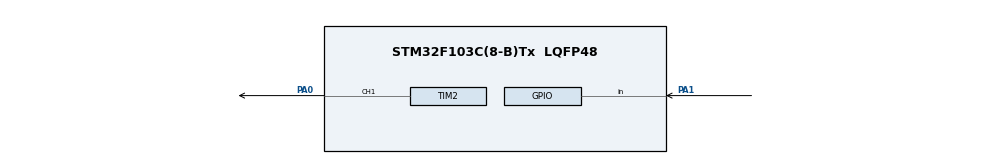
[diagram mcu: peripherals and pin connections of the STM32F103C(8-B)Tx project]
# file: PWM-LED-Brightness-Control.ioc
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Mcu.Family=STM32F1
Mcu.Name=STM32F103C(8-B)Tx
Mcu.Package=LQFP48
NVIC.PriorityGroup=NVIC_PRIORITYGROUP_4
PA0-WKUP.Signal=S_TIM2_CH1_ETR
PA1.GPIO_PuPd=GPIO_PULLUP
PA1.Signal=GPIO_Input
ProjectManager.HeapSize=0x200
ProjectManager.StackSize=0x400
ProjectManager.TargetToolchain=STM32CubeIDE
RCC.APB1Freq_Value=8000000
RCC.APB2Freq_Value=8000000
SH.S_TIM2_CH1_ETR.0=TIM2_CH1,PWM Generation1 CH1
TIM2.Channel-PWM\ Generation1\ CH1=TIM_CHANNEL_1
TIM2.Period=999
TIM2.Prescaler=71
VP_SYS_VS_ND.Mode=No_Debug
board=custom

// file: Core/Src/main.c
/* USER CODE BEGIN Header */
/**
  ******************************************************************************
  * @file           : main.c
  * @brief          : Main program body
  ******************************************************************************
  * @attention
  *
  * Copyright (c) 2026 STMicroelectronics.
  * All rights reserved.
  *
  * This software is licensed under terms that can be found in the LICENSE file
  * in the root directory of this software component.
  * If no LICENSE file comes with this software, it is provided AS-IS.
  *
  ******************************************************************************
  */
/* USER CODE END Header */
#include "main.h"

TIM_HandleTypeDef htim2;

void SystemClock_Config(void);
static void MX_GPIO_Init(void);
static void MX_TIM2_Init(void);

int main(void)
{

  /* MCU Configuration--------------------------------------------------------*/

  /* Reset of all peripherals, Initializes the Flash interface and the Systick. */
  HAL_Init();

  /* Configure the system clock */
  SystemClock_Config();

  /* Initialize all configured peripherals */
  MX_GPIO_Init();
  MX_TIM2_Init();

  /* Infinite loop */
  /* USER CODE BEGIN WHILE */

  /* --- Peripheral initialization (before while(1)) --- */
  /* USER CODE BEGIN 2 */
  /* 1. Start PWM and set initial duty to 0% BEFORE while(1) */
  HAL_TIM_PWM_Start(&htim2, TIM_CHANNEL_1);
  __HAL_TIM_SET_COMPARE(&htim2, TIM_CHANNEL_1, 0);

  uint8_t prv_btn = GPIO_PIN_SET;
  uint8_t brightness = 0;
  uint32_t last_press_time = 0;
  /* USER CODE END 2 */

  /* Infinite loop */
  /* USER CODE BEGIN WHILE */
  while (1)
  {
      uint8_t button = HAL_GPIO_ReadPin(GPIOA, GPIO_PIN_1);

      /* Detect falling edge: button pressed (Active-Low with Pull-Up) */
      if (button == GPIO_PIN_RESET && prv_btn == GPIO_PIN_SET)
      {

          if ((HAL_GetTick() - last_press_time) > 100)
          {
              if (brightness >= 100)
              {
                  brightness = 0;
              }
              else
              {
                  brightness += 10;
              }

              /* With ARR = 999:
               * 0%   -> 0
               * 20%  -> 200
               * 40%  -> 400
               * 60%  -> 600
               * 80%  -> 800
               * 100% -> 1000 (fully ON)
               */
              uint32_t pulse = (brightness * 1000) / 100;
              __HAL_TIM_SET_COMPARE(&htim2, TIM_CHANNEL_1, pulse);

              last_press_time = HAL_GetTick();
          }
      }

      prv_btn = button;

      /* USER CODE END WHILE */
  }
  /* USER CODE END 3 */
}

void SystemClock_Config(void)
{
  RCC_OscInitTypeDef RCC_OscInitStruct = {0};
  RCC_ClkInitTypeDef RCC_ClkInitStruct = {0};

  /** Initializes the RCC Oscillators according to the specified parameters
  * in the RCC_OscInitTypeDef structure.
  */
  RCC_OscInitStruct.OscillatorType = RCC_OSCILLATORTYPE_HSI;
  RCC_OscInitStruct.HSIState = RCC_HSI_ON;
  RCC_OscInitStruct.HSICalibrationValue = RCC_HSICALIBRATION_DEFAULT;
  RCC_OscInitStruct.PLL.PLLState = RCC_PLL_NONE;
  if (HAL_RCC_OscConfig(&RCC_OscInitStruct) != HAL_OK)
  {
    Error_Handler();
  }

  /** Initializes the CPU, AHB and APB buses clocks
  */
  RCC_ClkInitStruct.ClockType = RCC_CLOCKTYPE_HCLK|RCC_CLOCKTYPE_SYSCLK
                              |RCC_CLOCKTYPE_PCLK1|RCC_CLOCKTYPE_PCLK2;
  RCC_ClkInitStruct.SYSCLKSource = RCC_SYSCLKSOURCE_HSI;
  RCC_ClkInitStruct.AHBCLKDivider = RCC_SYSCLK_DIV1;
  RCC_ClkInitStruct.APB1CLKDivider = RCC_HCLK_DIV1;
  RCC_ClkInitStruct.APB2CLKDivider = RCC_HCLK_DIV1;

  if (HAL_RCC_ClockConfig(&RCC_ClkInitStruct, FLASH_LATENCY_0) != HAL_OK)
  {
    Error_Handler();
  }
}

static void MX_TIM2_Init(void)
{

  TIM_MasterConfigTypeDef sMasterConfig = {0};
  TIM_OC_InitTypeDef sConfigOC = {0};

  htim2.Instance = TIM2;
  htim2.Init.Prescaler = 71;
  htim2.Init.CounterMode = TIM_COUNTERMODE_UP;
  htim2.Init.Period = 999;
  htim2.Init.ClockDivision = TIM_CLOCKDIVISION_DIV1;
  htim2.Init.AutoReloadPreload = TIM_AUTORELOAD_PRELOAD_DISABLE;
  if (HAL_TIM_PWM_Init(&htim2) != HAL_OK)
  {
    Error_Handler();
  }
  sMasterConfig.MasterOutputTrigger = TIM_TRGO_RESET;
  sMasterConfig.MasterSlaveMode = TIM_MASTERSLAVEMODE_DISABLE;
  if (HAL_TIMEx_MasterConfigSynchronization(&htim2, &sMasterConfig) != HAL_OK)
  {
    Error_Handler();
  }
  sConfigOC.OCMode = TIM_OCMODE_PWM1;
  sConfigOC.Pulse = 0;
  sConfigOC.OCPolarity = TIM_OCPOLARITY_HIGH;
  sConfigOC.OCFastMode = TIM_OCFAST_DISABLE;
  if (HAL_TIM_PWM_ConfigChannel(&htim2, &sConfigOC, TIM_CHANNEL_1) != HAL_OK)
  {
    Error_Handler();
  }
  HAL_TIM_MspPostInit(&htim2);

}

static void MX_GPIO_Init(void)
{
  GPIO_InitTypeDef GPIO_InitStruct = {0};

  /* GPIO Ports Clock Enable */
  __HAL_RCC_GPIOA_CLK_ENABLE();

  /*Configure GPIO pin : PA1 */
  GPIO_InitStruct.Pin = GPIO_PIN_1;
  GPIO_InitStruct.Mode = GPIO_MODE_INPUT;
  GPIO_InitStruct.Pull = GPIO_PULLUP;
  HAL_GPIO_Init(GPIOA, &GPIO_InitStruct);

}

void Error_Handler(void)
{
  __disable_irq();
  while (1)
  {
  }
}
